# nrf7140_application register map
Vendor: Nordic Semiconductor; Series: nRF71; File version: 1
CPU: CM33 r0p4, little endian, MPU, FPU, 3 interrupt priority bits, 480 interrupts, 8 SAU regions
Registers are 32-bit, read-write, reset 0x0 unless marked. A register's access mark holds for its fields unless they carry their own. Offsets are from the block's base; [hi:lo] are bit positions; lines under a group give offsets from that group; {n}, {i} and the like mark numbered series; 'fields as' and 'values as' point back to an identical list.

## GLOBAL_DISPC_NS (part 1 of 3) — DISPC
Base 0x49004000
0x100 EVENTS_CORE — Event indicating that interrupt triggered at DISPC core
  [0] EVENTS_CORE
    0=NotGenerated (Event not generated); 1=Generated (Event generated)
0x104 EVENTS_UNDERRUN — Event indicating that underrun triggered in the DISPC core FIFO
  [0] EVENTS_UNDERRUN
    values as EVENTS_CORE.EVENTS_CORE
0x108 EVENTS_LOWBUFFER — Event indicating a low level condition in the DISPC core FIFO
  [0] EVENTS_LOWBUFFER
    values as EVENTS_CORE.EVENTS_CORE
0x10C EVENTS_HSYNC — Horizontal synchronization timing signal active edge.
  [0] EVENTS_HSYNC
    values as EVENTS_CORE.EVENTS_CORE
0x110 EVENTS_VSYNC — Vertical synchronization timing signal active edge.
  [0] EVENTS_VSYNC
    values as EVENTS_CORE.EVENTS_CORE
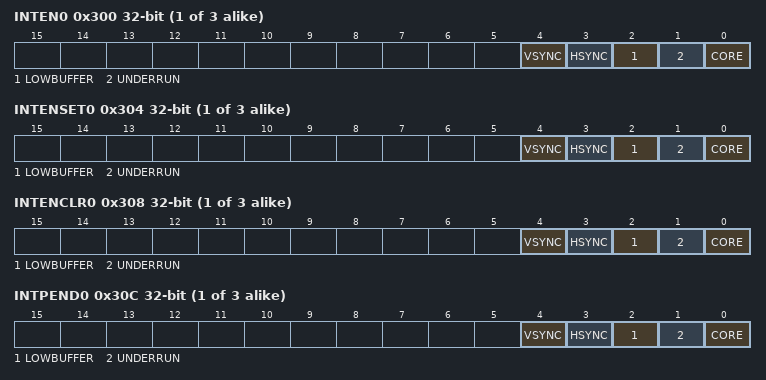
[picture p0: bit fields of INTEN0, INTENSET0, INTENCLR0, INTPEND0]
{0x300+0x10*i} INTEN{i} (i=0..2) — Enable or disable interrupt
  [all] fields
    0=Disabled; 1=Enabled
  [4] VSYNC — Enable or disable interrupt for event VSYNC
  [3] HSYNC — Enable or disable interrupt for event HSYNC
  [2] LOWBUFFER — Enable or disable interrupt for event LOWBUFFER
  [1] UNDERRUN — Enable or disable interrupt for event UNDERRUN
  [0] CORE — Enable or disable interrupt for event CORE
{0x304+0x10*i} INTENSET{i} (i=0..2) — Enable interrupt
  [all] fields
    on read: 0=Disabled (Read: Disabled); 1=Enabled (Read: Enabled) | on write: 1=Set (Enable)
  [4] VSYNC — Write '1' to enable interrupt for event VSYNC
  [3] HSYNC — Write '1' to enable interrupt for event HSYNC
  [2] LOWBUFFER — Write '1' to enable interrupt for event LOWBUFFER
  [1] UNDERRUN — Write '1' to enable interrupt for event UNDERRUN
  [0] CORE — Write '1' to enable interrupt for event CORE
{0x308+0x10*i} INTENCLR{i} (i=0..2) — Disable interrupt
  [all] fields
    on read: 0=Disabled (Read: Disabled); 1=Enabled (Read: Enabled) | on write: 1=Clear (Disable)
  [4] VSYNC — Write '1' to disable interrupt for event VSYNC
  [3] HSYNC — Write '1' to disable interrupt for event HSYNC
  [2] LOWBUFFER — Write '1' to disable interrupt for event LOWBUFFER
  [1] UNDERRUN — Write '1' to disable interrupt for event UNDERRUN
  [0] CORE — Write '1' to disable interrupt for event CORE
{0x30C+0x10*i} INTPEND{i} ro (i=0..2) — Pending interrupts
  [all] fields
    on read: 0=NotPending (Read: Not pending); 1=Pending (Read: Pending)
  [4] VSYNC — Read pending status of interrupt for event VSYNC
  [3] HSYNC — Read pending status of interrupt for event HSYNC
  [2] LOWBUFFER — Read pending status of interrupt for event LOWBUFFER
  [1] UNDERRUN — Read pending status of interrupt for event UNDERRUN
  [0] CORE — Read pending status of interrupt for event CORE
0x500 ENABLE — Enable Display Controller.
  [0] EN — Enable
    0=Disabled (DISPC disabled.); 1=Enabled (DISPC enabled.)
0x504 REMAPBITS — Register denoting how many of the address bits on the AXI bus of the DC is getting remapped, 0 (default) up to 31.
  [4:0] REMAPBITS
0x508 REMAPADDRESS — Address (lowest bit unused) which is substituting REMAPBITS of address bits, starting at the top. Bits which are not substituted do not have any effect
0x600 PSEL group — Unspecified
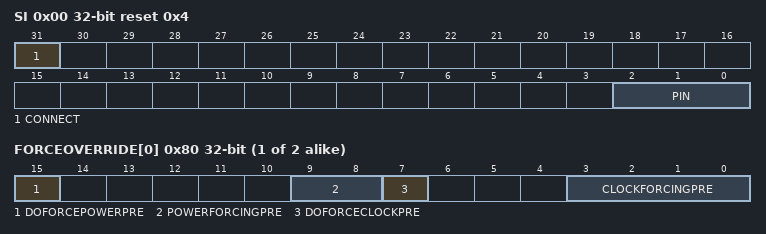
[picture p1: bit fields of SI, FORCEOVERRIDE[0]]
  0x00 SI reset 0x4 — Pin select for SI signal
    [31] CONNECT — Connection
      1=Disconnected; 0=Connected
    [2:0] PIN — Which pin to connect the SI signal to
      {v}=SD{v} (Connected to SD{v}) (v=0..3); 4=SI (Connected to a dedicated SI pin)
0xF00 PCGCSLAVE group — Unspecified
  {0x0+4j} PENALTY[{j}] (j=0..1) reset 0xFFFFFFFC — Description collection: Penalty level for power/clock pair n. When FULL_PCP_ZERO feature is not supported, PENALTY[0] address overlaps the PENALTY0 address and register description for PENALTY[0] is not valid.
    [1:0] PENALTY — Penalty level
  0x00 PENALTY0 (alternate view of PENALTY[*]) — Penalty level for power/clock pair 0. The register description is valid only when FULL_PCP_ZERO feature is not supported
    [1:0] PENALTY ro — Penalty level
  {0x80+4j} FORCEOVERRIDE[{j}] (j=0..1) — Description collection: Force override of power/clock pair n.
    [15] DOFORCEPOWERPRE, [9:8] POWERFORCINGPRE, [7] DOFORCECLOCKPRE, [3:0] CLOCKFORCINGPRE
